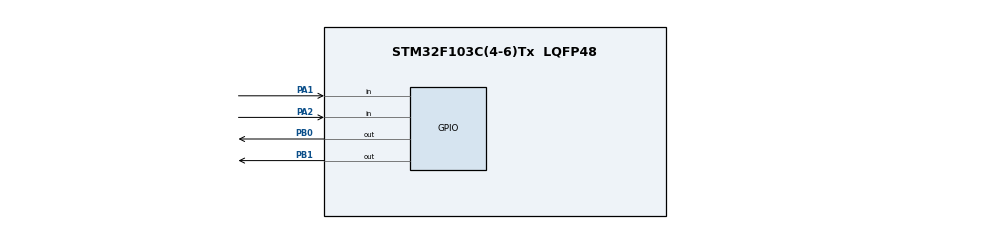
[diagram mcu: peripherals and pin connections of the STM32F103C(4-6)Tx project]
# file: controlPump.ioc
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Mcu.Family=STM32F1
RCC.PLLSourceVirtual=RCC_PLLSOURCE_HSE
PA2.GPIO_PuPd=GPIO_PULLUP
PD1-OSC_OUT.Mode=HSE-External-Oscillator
PD0-OSC_IN.Signal=RCC_OSC_IN
VP_SYS_VS_ND.Mode=No_Debug
RCC.SYSCLKSource=RCC_SYSCLKSOURCE_PLLCLK
ProjectManager.StackSize=0x400
PD1-OSC_OUT.Signal=RCC_OSC_OUT
ProjectManager.TargetToolchain=STM32CubeIDE
RCC.HCLKFreq_Value=16000000
RCC.APB2TimFreq_Value=16000000
RCC.USBFreq_Value=16000000
PA1.GPIO_PuPd=GPIO_PULLUP
PA1.Signal=GPIO_Input
RCC.AHBFreq_Value=16000000
PD0-OSC_IN.Mode=HSE-External-Oscillator
board=custom
RCC.APB2Freq_Value=16000000
Mcu.Name=STM32F103C(4-6)Tx
PA2.Signal=GPIO_Input
RCC.SYSCLKFreq_VALUE=16000000
Mcu.Package=LQFP48
PB1.Signal=GPIO_Output
ProjectManager.HeapSize=0x200
NVIC.PriorityGroup=NVIC_PRIORITYGROUP_4
RCC.APB1TimFreq_Value=16000000
RCC.APB1Freq_Value=16000000
PB0.Signal=GPIO_Output

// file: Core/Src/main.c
/* USER CODE BEGIN Header */
/**
  ******************************************************************************
  * @file           : main.c
  * @brief          : Main program body
  ******************************************************************************
  * @attention
  *
  * <h2><center>&copy; Copyright (c) 2023 STMicroelectronics.
  * All rights reserved.</center></h2>
  *
  * This software component is licensed by ST under BSD 3-Clause license,
  * the "License"; You may not use this file except in compliance with the
  * License. You may obtain a copy of the License at:
  *                        opensource.org/licenses/BSD-3-Clause
  *
  ******************************************************************************
  */
/* USER CODE END Header */
#include "main.h"
#include "pump_module.h"

//#include "pump_module.h"

void SystemClock_Config(void);
static void MX_GPIO_Init(void);

int main(void)
{

  /* MCU Configuration--------------------------------------------------------*/

  /* Reset of all peripherals, Initializes the Flash interface and the Systick. */

  LL_APB2_GRP1_EnableClock(LL_APB2_GRP1_PERIPH_AFIO);
  LL_APB1_GRP1_EnableClock(LL_APB1_GRP1_PERIPH_PWR);

  NVIC_SetPriorityGrouping(NVIC_PRIORITYGROUP_4);

  /* System interrupt init*/

  /** DISABLE: JTAG-DP Disabled and SW-DP Disabled
  */
  LL_GPIO_AF_DisableRemap_SWJ();

  /* Configure the system clock */
  SystemClock_Config();

  /* Initialize all configured peripherals */
  MX_GPIO_Init();

  /* Infinite loop */
  /* USER CODE BEGIN WHILE */
  LL_SYSTICK_EnableIT();
  init_State();
  while (1)
  {
    /* USER CODE END WHILE */
	  stateUpdate();
  }
}

void SystemClock_Config(void)
{
  LL_FLASH_SetLatency(LL_FLASH_LATENCY_0);
  while(LL_FLASH_GetLatency()!= LL_FLASH_LATENCY_0)
  {
  }
  LL_RCC_HSE_Enable();

   /* Wait till HSE is ready */
  while(LL_RCC_HSE_IsReady() != 1)
  {

  }
  LL_RCC_PLL_ConfigDomain_SYS(LL_RCC_PLLSOURCE_HSE_DIV_1, LL_RCC_PLL_MUL_2);
  LL_RCC_PLL_Enable();

   /* Wait till PLL is ready */
  while(LL_RCC_PLL_IsReady() != 1)
  {

  }
  LL_RCC_SetAHBPrescaler(LL_RCC_SYSCLK_DIV_1);
  LL_RCC_SetAPB1Prescaler(LL_RCC_APB1_DIV_1);
  LL_RCC_SetAPB2Prescaler(LL_RCC_APB2_DIV_1);
  LL_RCC_SetSysClkSource(LL_RCC_SYS_CLKSOURCE_PLL);

   /* Wait till System clock is ready */
  while(LL_RCC_GetSysClkSource() != LL_RCC_SYS_CLKSOURCE_STATUS_PLL)
  {

  }
  LL_Init1msTick(16000000);
  LL_SetSystemCoreClock(16000000);
}

static void MX_GPIO_Init(void)
{
  LL_GPIO_InitTypeDef GPIO_InitStruct = {0};

  /* GPIO Ports Clock Enable */
  LL_APB2_GRP1_EnableClock(LL_APB2_GRP1_PERIPH_GPIOD);
  LL_APB2_GRP1_EnableClock(LL_APB2_GRP1_PERIPH_GPIOA);
  LL_APB2_GRP1_EnableClock(LL_APB2_GRP1_PERIPH_GPIOB);

  /**/
  LL_GPIO_ResetOutputPin(GPIOB, LL_GPIO_PIN_0|LL_GPIO_PIN_1);

  /**/
  GPIO_InitStruct.Pin = LL_GPIO_PIN_1|LL_GPIO_PIN_2;
  GPIO_InitStruct.Mode = LL_GPIO_MODE_INPUT;
  GPIO_InitStruct.Pull = LL_GPIO_PULL_UP;
  LL_GPIO_Init(GPIOA, &GPIO_InitStruct);

  /**/
  GPIO_InitStruct.Pin = LL_GPIO_PIN_0|LL_GPIO_PIN_1;
  GPIO_InitStruct.Mode = LL_GPIO_MODE_OUTPUT;
  GPIO_InitStruct.Speed = LL_GPIO_SPEED_FREQ_LOW;
  GPIO_InitStruct.OutputType = LL_GPIO_OUTPUT_PUSHPULL;
  LL_GPIO_Init(GPIOB, &GPIO_InitStruct);

}

void Error_Handler(void)
{
  __disable_irq();
  while (1)
  {
  }
}

/************************ (C) COPYRIGHT STMicroelectronics *****END OF FILE****/
